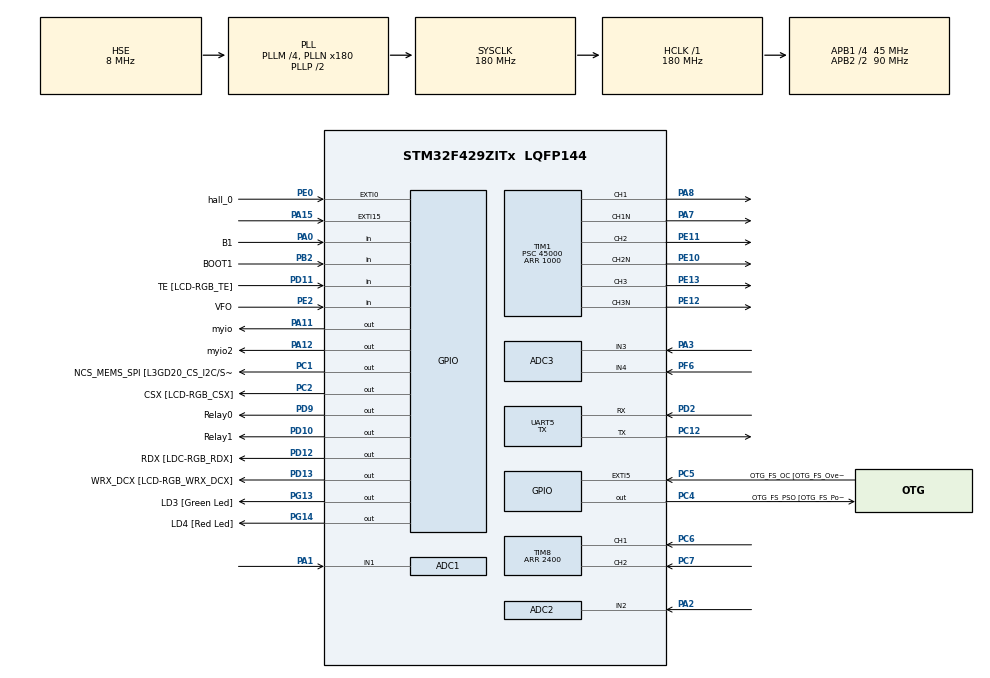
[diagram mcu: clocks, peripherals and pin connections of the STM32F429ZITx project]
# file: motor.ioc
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ADC1.Channel-12\#ChannelRegularConversion=ADC_CHANNEL_1
ADC1.Channel-13\#ChannelInjectedConversion=ADC_CHANNEL_1
ADC1.EOCSelection=ADC_EOC_SEQ_CONV
ADC1.EnableAnalogWatchDog=true
ADC1.ExternalTrigInjecConv=ADC_EXTERNALTRIGINJECCONV_T1_TRGO
ADC1.ExternalTrigInjecConvEdge=ADC_EXTERNALTRIGINJECCONVEDGE_FALLING
ADC1.InjNumberOfConversion=1
ADC1.InjectedOffset-13\#ChannelInjectedConversion=0
ADC1.InjectedRank-13\#ChannelInjectedConversion=1
ADC1.Mode=ADC_TRIPLEMODE_INJECSIMULT
ADC1.NbrOfConversionFlag=1
ADC1.Rank-12\#ChannelRegularConversion=1
ADC1.SamplingTime-12\#ChannelRegularConversion=ADC_SAMPLETIME_3CYCLES
ADC1.SamplingTime-13\#ChannelInjectedConversion=ADC_SAMPLETIME_3CYCLES
ADC1.WatchdogChannel=ADC_CHANNEL_1
ADC1.master=1
ADC2.Channel-22\#ChannelRegularConversion=ADC_CHANNEL_2
ADC2.Channel-23\#ChannelInjectedConversion=ADC_CHANNEL_2
ADC2.InjNumberOfConversion=1
ADC2.InjectedOffset-23\#ChannelInjectedConversion=0
ADC2.InjectedRank-23\#ChannelInjectedConversion=1
ADC2.Mode=ADC_TRIPLEMODE_INJECSIMULT
ADC2.NbrOfConversionFlag=1
ADC2.Rank-22\#ChannelRegularConversion=1
ADC2.SamplingTime-22\#ChannelRegularConversion=ADC_SAMPLETIME_3CYCLES
ADC2.SamplingTime-23\#ChannelInjectedConversion=ADC_SAMPLETIME_3CYCLES
ADC3.Channel-2\#ChannelRegularConversion=ADC_CHANNEL_3
ADC3.Channel-3\#ChannelInjectedConversion=ADC_CHANNEL_3
ADC3.InjNumberOfConversion=1
ADC3.InjectedOffset-3\#ChannelInjectedConversion=0
ADC3.InjectedRank-3\#ChannelInjectedConversion=1
ADC3.Mode=ADC_TRIPLEMODE_INJECSIMULT
ADC3.NbrOfConversionFlag=1
ADC3.Rank-2\#ChannelRegularConversion=1
ADC3.SamplingTime-2\#ChannelRegularConversion=ADC_SAMPLETIME_3CYCLES
ADC3.SamplingTime-3\#ChannelInjectedConversion=ADC_SAMPLETIME_3CYCLES
Mcu.Family=STM32F4
Mcu.Name=STM32F429ZITx
Mcu.Package=LQFP144
NVIC.ADC_IRQn=true\:0\:0\:false\:false\:true\:true\:true
NVIC.EXTI0_IRQn=true\:0\:0\:false\:false\:true\:true\:true
NVIC.PriorityGroup=NVIC_PRIORITYGROUP_4
NVIC.TIM1_CC_IRQn=true\:0\:0\:false\:false\:true\:true\:true
NVIC.TIM1_UP_TIM10_IRQn=true\:0\:0\:false\:false\:true\:true\:true
NVIC.TIM6_DAC_IRQn=true\:0\:0\:false\:false\:true\:false\:true
NVIC.TimeBase=TIM6_DAC_IRQn
NVIC.TimeBaseIP=TIM6
NVIC.UART5_IRQn=true\:0\:0\:false\:false\:true\:true\:true
PA0/WKUP.GPIO_Label=B1
PA0/WKUP.Signal=GPIO_Input
PA1.Signal=ADCx_IN1
PA10.GPIO_Label=STLINK_TX [STM32F103CBT6_PA2]
PA10.Signal=USART1_RX
PA11.GPIO_Label=myio
PA11.Signal=GPIO_Output
PA12.GPIO_Label=myio2
PA12.Signal=GPIO_Output
PA13.GPIO_Label=SWDIO
PA13.Mode=Serial_Wire
PA13.Signal=SYS_JTMS-SWDIO
PA14.GPIO_Label=SWCLK
PA14.Mode=Serial_Wire
PA14.Signal=SYS_JTCK-SWCLK
PA15.Signal=GPXTI15
PA2.Signal=ADCx_IN2
PA3.Signal=ADCx_IN3
PA4.GPIO_Label=VSYNC
PA4.GPIO_Mode=GPIO_MODE_AF_PP
PA4.GPIO_PuPd=GPIO_NOPULL
PA4.GPIO_Speed=GPIO_SPEED_FREQ_LOW
PA4.Signal=LTDC_VSYNC
PA6.GPIO_Label=G2
PA6.GPIO_Mode=GPIO_MODE_AF_PP
PA6.GPIO_PuPd=GPIO_NOPULL
PA6.GPIO_Speed=GPIO_SPEED_FREQ_LOW
PA6.Signal=LTDC_G2
PA7.GPIO_Speed=GPIO_SPEED_FREQ_HIGH
PA7.Mode=PWM Generation1 CH1 CH1N
PA7.Signal=TIM1_CH1N
PA8.GPIO_Speed=GPIO_SPEED_FREQ_HIGH
PA8.Signal=S_TIM1_CH1
PA9.GPIO_Label=STLINK_RX [STM32F103CBT6_PA3]
PA9.Signal=USART1_TX
PB0.GPIO_Label=R3
PB0.GPIO_Mode=GPIO_MODE_AF_PP
PB0.GPIO_PuPd=GPIO_NOPULL
PB0.GPIO_Speed=GPIO_SPEED_FREQ_LOW
PB0.Signal=LTDC_R3
PB1.Signal=TIM8_CH3N
PB10.GPIO_Label=G4
PB10.GPIO_Mode=GPIO_MODE_AF_PP
PB10.GPIO_PuPd=GPIO_NOPULL
PB10.GPIO_Speed=GPIO_SPEED_FREQ_LOW
PB10.Signal=LTDC_G4
PB11.GPIO_Label=G5
PB11.GPIO_Mode=GPIO_MODE_AF_PP
PB11.GPIO_PuPd=GPIO_NOPULL
PB11.GPIO_Speed=GPIO_SPEED_FREQ_LOW
PB11.Signal=LTDC_G5
PB12.GPIO_Label=OTG_HS_ID
PB12.GPIO_Mode=GPIO_MODE_AF_PP
PB12.GPIO_PuPd=GPIO_NOPULL
PB12.GPIO_Speed=GPIO_SPEED_FREQ_LOW
PB12.Signal=USB_OTG_HS_ID
PB13.GPIO_Label=VBUS_HS
PB13.GPIO_Mode=GPIO_MODE_INPUT
PB13.GPIO_PuPd=GPIO_NOPULL
PB13.Signal=USB_OTG_HS_VBUS
PB14.GPIO_Label=OTG_HS_DM
PB14.GPIO_Mode=GPIO_MODE_AF_PP
PB14.GPIO_PuPd=GPIO_NOPULL
PB14.GPIO_Speed=GPIO_SPEED_FREQ_LOW
PB14.Signal=USB_OTG_HS_DM
PB15.GPIO_Label=OTG_HS_DP
PB15.GPIO_Mode=GPIO_MODE_AF_PP
PB15.GPIO_PuPd=GPIO_NOPULL
PB15.GPIO_Speed=GPIO_SPEED_FREQ_LOW
PB15.Signal=USB_OTG_HS_DP
PB2/BOOT1.GPIO_Label=BOOT1
PB2/BOOT1.GPIO_Mode=GPIO_MODE_INPUT
PB2/BOOT1.GPIO_PuPd=GPIO_NOPULL
PB2/BOOT1.Signal=GPIO_Input
PB5.GPIO_Label=SDCKE1
PB5.GPIO_Mode=GPIO_MODE_AF_PP
PB5.GPIO_PuPd=GPIO_NOPULL
PB5.GPIO_Speed=GPIO_SPEED_FREQ_VERY_HIGH
PB5.Signal=FMC_SDCKE1
PB6.GPIO_Label=SDNE1 [SDRAM_CS]
PB6.GPIO_Mode=GPIO_MODE_AF_PP
PB6.GPIO_PuPd=GPIO_NOPULL
PB6.GPIO_Speed=GPIO_SPEED_FREQ_VERY_HIGH
PB6.Signal=FMC_SDNE1
PB8.GPIO_Label=B6
PB8.GPIO_Mode=GPIO_MODE_AF_PP
PB8.GPIO_PuPd=GPIO_NOPULL
PB8.GPIO_Speed=GPIO_SPEED_FREQ_LOW
PB8.Signal=LTDC_B6
PB9.GPIO_Label=B7
PB9.GPIO_Mode=GPIO_MODE_AF_PP
PB9.GPIO_PuPd=GPIO_NOPULL
PB9.GPIO_Speed=GPIO_SPEED_FREQ_LOW
PB9.Signal=LTDC_B7
PC0.GPIO_Label=SDNWE
PC0.GPIO_Mode=GPIO_MODE_AF_PP
PC0.GPIO_PuPd=GPIO_NOPULL
PC0.GPIO_Speed=GPIO_SPEED_FREQ_VERY_HIGH
PC0.Signal=FMC_SDNWE
PC1.GPIO_Label=NCS_MEMS_SPI [L3GD20_CS_I2C/SPI]
PC1.GPIO_Mode=GPIO_MODE_OUTPUT_PP
PC1.GPIO_PuPd=GPIO_NOPULL
PC1.GPIO_Speed=GPIO_SPEED_FREQ_LOW
PC1.Signal=GPIO_Output
PC10.GPIO_Label=R2
PC10.GPIO_Mode=GPIO_MODE_AF_PP
PC10.GPIO_PuPd=GPIO_NOPULL
PC10.GPIO_Speed=GPIO_SPEED_FREQ_LOW
PC10.Signal=LTDC_R2
PC12.Mode=Asynchronous
PC12.Signal=UART5_TX
PC14/OSC32_IN.GPIO_Label=PC14-OSC32_IN
PC14/OSC32_IN.Signal=RCC_OSC32_IN
PC15/OSC32_OUT.GPIO_Label=PC15-OSC32_OUT
PC15/OSC32_OUT.Signal=RCC_OSC32_OUT
PC2.GPIO_Label=CSX [LCD-RGB_CSX]
PC2.GPIO_Mode=GPIO_MODE_OUTPUT_PP
PC2.GPIO_PuPd=GPIO_NOPULL
PC2.GPIO_Speed=GPIO_SPEED_FREQ_LOW
PC2.Signal=GPIO_Output
PC4.GPIO_Label=OTG_FS_PSO [OTG_FS_PowerSwitchOn]
PC4.GPIO_Mode=GPIO_MODE_OUTPUT_PP
PC4.GPIO_PuPd=GPIO_NOPULL
PC4.GPIO_Speed=GPIO_SPEED_FREQ_LOW
PC4.Signal=GPIO_Output
PC5.GPIO_Label=OTG_FS_OC [OTG_FS_OverCurrent]
PC5.GPIO_ModeDefaultEXTI=GPIO_MODE_EVT_RISING
PC5.Signal=GPXTI5
PC6.Signal=S_TIM8_CH1
PC7.Signal=S_TIM8_CH2
PD0.GPIO_Label=D2
PD0.GPIO_Mode=GPIO_MODE_AF_PP
PD0.GPIO_PuPd=GPIO_NOPULL
PD0.GPIO_Speed=GPIO_SPEED_FREQ_VERY_HIGH
PD0.Signal=FMC_D2_DA2
PD1.GPIO_Label=D3
PD1.GPIO_Mode=GPIO_MODE_AF_PP
PD1.GPIO_PuPd=GPIO_NOPULL
PD1.GPIO_Speed=GPIO_SPEED_FREQ_VERY_HIGH
PD1.Signal=FMC_D3_DA3
PD10.GPIO_Label=Relay1
PD10.Signal=GPIO_Output
PD11.GPIO_Label=TE [LCD-RGB_TE]
PD11.GPIO_Mode=GPIO_MODE_INPUT
PD11.GPIO_PuPd=GPIO_NOPULL
PD11.Signal=GPIO_Input
PD12.GPIO_Label=RDX [LDC-RGB_RDX]
PD12.GPIO_Mode=GPIO_MODE_OUTPUT_PP
PD12.GPIO_PuPd=GPIO_NOPULL
PD12.GPIO_Speed=GPIO_SPEED_FREQ_LOW
PD12.Signal=GPIO_Output
PD13.GPIO_Label=WRX_DCX [LCD-RGB_WRX_DCX]
PD13.GPIO_Mode=GPIO_MODE_OUTPUT_PP
PD13.GPIO_PuPd=GPIO_NOPULL
PD13.GPIO_Speed=GPIO_SPEED_FREQ_LOW
PD13.Signal=GPIO_Output
PD14.GPIO_Label=D0
PD14.GPIO_Mode=GPIO_MODE_AF_PP
PD14.GPIO_PuPd=GPIO_NOPULL
PD14.GPIO_Speed=GPIO_SPEED_FREQ_VERY_HIGH
PD14.Signal=FMC_D0_DA0
PD15.GPIO_Label=D1
PD15.GPIO_Mode=GPIO_MODE_AF_PP
PD15.GPIO_PuPd=GPIO_NOPULL
PD15.GPIO_Speed=GPIO_SPEED_FREQ_VERY_HIGH
PD15.Signal=FMC_D1_DA1
PD2.Mode=Asynchronous
PD2.Signal=UART5_RX
PD3.GPIO_Label=G7
PD3.GPIO_Mode=GPIO_MODE_AF_PP
PD3.GPIO_PuPd=GPIO_NOPULL
PD3.GPIO_Speed=GPIO_SPEED_FREQ_LOW
PD3.Signal=LTDC_G7
PD6.GPIO_Label=B2
PD6.GPIO_Mode=GPIO_MODE_AF_PP
PD6.GPIO_PuPd=GPIO_NOPULL
PD6.GPIO_Speed=GPIO_SPEED_FREQ_LOW
PD6.Signal=LTDC_B2
PD8.GPIO_Label=D13
PD8.GPIO_Mode=GPIO_MODE_AF_PP
PD8.GPIO_PuPd=GPIO_NOPULL
PD8.GPIO_Speed=GPIO_SPEED_FREQ_VERY_HIGH
PD8.Signal=FMC_D13_DA13
PD9.GPIO_Label=Relay0
PD9.Signal=GPIO_Output
PE0.GPIO_Label=hall_0
PE0.GPIO_ModeDefaultEXTI=GPIO_MODE_IT_RISING
PE0.GPIO_PuPd=GPIO_PULLUP
PE0.Signal=GPXTI0
PE10.GPIO_Speed=GPIO_SPEED_FREQ_HIGH
PE10.Mode=PWM Generation2 CH2 CH2N
PE10.Signal=TIM1_CH2N
PE11.GPIO_Speed=GPIO_SPEED_FREQ_HIGH
PE11.Signal=S_TIM1_CH2
PE12.GPIO_Speed=GPIO_SPEED_FREQ_HIGH
PE12.Mode=PWM Generation3 CH3 CH3N
PE12.Signal=TIM1_CH3N
PE13.GPIO_Speed=GPIO_SPEED_FREQ_HIGH
PE13.Signal=S_TIM1_CH3
PE14.GPIO_Label=D11
PE14.GPIO_Mode=GPIO_MODE_AF_PP
PE14.GPIO_PuPd=GPIO_NOPULL
PE14.GPIO_Speed=GPIO_SPEED_FREQ_VERY_HIGH
PE14.Signal=FMC_D11_DA11
PE15.GPIO_Label=D12
PE15.GPIO_Mode=GPIO_MODE_AF_PP
PE15.GPIO_PuPd=GPIO_NOPULL
PE15.GPIO_Speed=GPIO_SPEED_FREQ_VERY_HIGH
PE15.Signal=FMC_D12_DA12
PE2.GPIO_Label=VFO
PE2.GPIO_PuPd=GPIO_PULLUP
PE2.Signal=GPIO_Input
PE7.GPIO_Label=D4
PE7.GPIO_Mode=GPIO_MODE_AF_PP
PE7.GPIO_PuPd=GPIO_NOPULL
PE7.GPIO_Speed=GPIO_SPEED_FREQ_VERY_HIGH
PE7.Signal=FMC_D4_DA4
PE8.GPIO_Label=D5
PE8.GPIO_Mode=GPIO_MODE_AF_PP
PE8.GPIO_PuPd=GPIO_NOPULL
PE8.GPIO_Speed=GPIO_SPEED_FREQ_VERY_HIGH
PE8.Signal=FMC_D5_DA5
PE9.GPIO_Label=D6
PE9.GPIO_Mode=GPIO_MODE_AF_PP
PE9.GPIO_PuPd=GPIO_NOPULL
PE9.GPIO_Speed=GPIO_SPEED_FREQ_VERY_HIGH
PE9.Signal=FMC_D6_DA6
PF0.GPIO_Label=A0
PF0.GPIO_Mode=GPIO_MODE_AF_PP
PF0.GPIO_PuPd=GPIO_NOPULL
PF0.GPIO_Speed=GPIO_SPEED_FREQ_VERY_HIGH
PF0.Signal=FMC_A0
PF1.GPIO_Label=A1
PF1.GPIO_Mode=GPIO_MODE_AF_PP
PF1.GPIO_PuPd=GPIO_NOPULL
PF1.GPIO_Speed=GPIO_SPEED_FREQ_VERY_HIGH
PF1.Signal=FMC_A1
PF10.GPIO_Label=ENABLE [LCD-RGB_ENABLE]
PF10.GPIO_Mode=GPIO_MODE_AF_PP
PF10.GPIO_PuPd=GPIO_NOPULL
PF10.GPIO_Speed=GPIO_SPEED_FREQ_LOW
PF10.Signal=LTDC_DE
PF11.GPIO_Label=SDNRAS
PF11.GPIO_Mode=GPIO_MODE_AF_PP
PF11.GPIO_PuPd=GPIO_NOPULL
PF11.GPIO_Speed=GPIO_SPEED_FREQ_VERY_HIGH
PF11.Signal=FMC_SDNRAS
PF12.GPIO_Label=A6
PF12.GPIO_Mode=GPIO_MODE_AF_PP
PF12.GPIO_PuPd=GPIO_NOPULL
PF12.GPIO_Speed=GPIO_SPEED_FREQ_VERY_HIGH
PF12.Signal=FMC_A6
PF13.GPIO_Label=A7
PF13.GPIO_Mode=GPIO_MODE_AF_PP
PF13.GPIO_PuPd=GPIO_NOPULL
PF13.GPIO_Speed=GPIO_SPEED_FREQ_VERY_HIGH
PF13.Signal=FMC_A7
PF14.GPIO_Label=A8
PF14.GPIO_Mode=GPIO_MODE_AF_PP
PF14.GPIO_PuPd=GPIO_NOPULL
PF14.GPIO_Speed=GPIO_SPEED_FREQ_VERY_HIGH
PF14.Signal=FMC_A8
PF15.GPIO_Label=A9
PF15.GPIO_Mode=GPIO_MODE_AF_PP
PF15.GPIO_PuPd=GPIO_NOPULL
PF15.GPIO_Speed=GPIO_SPEED_FREQ_VERY_HIGH
PF15.Signal=FMC_A9
PF2.GPIO_Label=A2
PF2.GPIO_Mode=GPIO_MODE_AF_PP
PF2.GPIO_PuPd=GPIO_NOPULL
PF2.GPIO_Speed=GPIO_SPEED_FREQ_VERY_HIGH
PF2.Signal=FMC_A2
PF3.GPIO_Label=A3
PF3.GPIO_Mode=GPIO_MODE_AF_PP
PF3.GPIO_PuPd=GPIO_NOPULL
PF3.GPIO_Speed=GPIO_SPEED_FREQ_VERY_HIGH
PF3.Signal=FMC_A3
PF4.GPIO_Label=A4
PF4.GPIO_Mode=GPIO_MODE_AF_PP
PF4.GPIO_PuPd=GPIO_NOPULL
PF4.GPIO_Speed=GPIO_SPEED_FREQ_VERY_HIGH
PF4.Signal=FMC_A4
PF5.GPIO_Label=A5
PF5.GPIO_Mode=GPIO_MODE_AF_PP
PF5.GPIO_PuPd=GPIO_NOPULL
PF5.GPIO_Speed=GPIO_SPEED_FREQ_VERY_HIGH
PF5.Signal=FMC_A5
PF6.Mode=IN4
PF6.Signal=ADC3_IN4
PF7.GPIO_Label=SPI5_SCK [L3GD20_SCL/SPC]
PF7.GPIO_Mode=GPIO_MODE_AF_PP
PF7.GPIO_PuPd=GPIO_NOPULL
PF7.GPIO_Speed=GPIO_SPEED_FREQ_LOW
PF7.Signal=SPI5_SCK
PF8.GPIO_Label=SPI5_MISO [L3GD20_SDO]
PF8.GPIO_Mode=GPIO_MODE_AF_PP
PF8.GPIO_PuPd=GPIO_NOPULL
PF8.GPIO_Speed=GPIO_SPEED_FREQ_LOW
PF8.Signal=SPI5_MISO
PF9.GPIO_Label=SPI5_MOSI [L3GD20_SDA/SDI/SDO]
PF9.GPIO_Mode=GPIO_MODE_AF_PP
PF9.GPIO_PuPd=GPIO_NOPULL
PF9.GPIO_Speed=GPIO_SPEED_FREQ_LOW
PF9.Signal=SPI5_MOSI
PG0.GPIO_Label=A10
PG0.GPIO_Mode=GPIO_MODE_AF_PP
PG0.GPIO_PuPd=GPIO_NOPULL
PG0.GPIO_Speed=GPIO_SPEED_FREQ_VERY_HIGH
PG0.Signal=FMC_A10
PG1.GPIO_Label=A11
PG1.GPIO_Mode=GPIO_MODE_AF_PP
PG1.GPIO_PuPd=GPIO_NOPULL
PG1.GPIO_Speed=GPIO_SPEED_FREQ_VERY_HIGH
PG1.Signal=FMC_A11
PG10.GPIO_Label=G3
PG10.GPIO_Mode=GPIO_MODE_AF_PP
PG10.GPIO_PuPd=GPIO_NOPULL
PG10.GPIO_Speed=GPIO_SPEED_FREQ_LOW
PG10.Signal=LTDC_G3
PG11.GPIO_Label=B3
PG11.GPIO_Mode=GPIO_MODE_AF_PP
PG11.GPIO_PuPd=GPIO_NOPULL
PG11.GPIO_Speed=GPIO_SPEED_FREQ_LOW
PG11.Signal=LTDC_B3
PG12.GPIO_Label=B4
PG12.GPIO_Mode=GPIO_MODE_AF_PP
PG12.GPIO_PuPd=GPIO_NOPULL
PG12.GPIO_Speed=GPIO_SPEED_FREQ_LOW
PG12.Signal=LTDC_B4
PG13.GPIO_Label=LD3 [Green Led]
PG13.GPIO_Mode=GPIO_MODE_OUTPUT_PP
PG13.GPIO_PuPd=GPIO_NOPULL
PG13.GPIO_Speed=GPIO_SPEED_FREQ_LOW
PG13.Signal=GPIO_Output
PG14.GPIO_Label=LD4 [Red Led]
PG14.GPIO_Mode=GPIO_MODE_OUTPUT_PP
PG14.GPIO_PuPd=GPIO_NOPULL
PG14.GPIO_Speed=GPIO_SPEED_FREQ_LOW
PG14.Signal=GPIO_Output
PG15.GPIO_Label=SDNCAS
PG15.GPIO_Mode=GPIO_MODE_AF_PP
PG15.GPIO_PuPd=GPIO_NOPULL
PG15.GPIO_Speed=GPIO_SPEED_FREQ_VERY_HIGH
PG15.Signal=FMC_SDNCAS
PG4.GPIO_Label=BA0
PG4.GPIO_Mode=GPIO_MODE_AF_PP
PG4.GPIO_PuPd=GPIO_NOPULL
PG4.GPIO_Speed=GPIO_SPEED_FREQ_VERY_HIGH
PG4.Signal=FMC_A14_BA0
PG5.GPIO_Label=BA1
PG5.GPIO_Mode=GPIO_MODE_AF_PP
PG5.GPIO_PuPd=GPIO_NOPULL
PG5.GPIO_Speed=GPIO_SPEED_FREQ_VERY_HIGH
PG5.Signal=FMC_A15_BA1
PG6.GPIO_Label=R7
PG6.GPIO_Mode=GPIO_MODE_AF_PP
PG6.GPIO_PuPd=GPIO_NOPULL
PG6.GPIO_Speed=GPIO_SPEED_FREQ_LOW
PG6.Signal=LTDC_R7
PG7.GPIO_Label=DOTCLK [LCT-RGB_DOTCLK]
PG7.GPIO_Mode=GPIO_MODE_AF_PP
PG7.GPIO_PuPd=GPIO_NOPULL
PG7.GPIO_Speed=GPIO_SPEED_FREQ_LOW
PG7.Signal=LTDC_CLK
PG8.GPIO_Label=SDCLK
PG8.GPIO_Mode=GPIO_MODE_AF_PP
PG8.GPIO_PuPd=GPIO_NOPULL
PG8.GPIO_Speed=GPIO_SPEED_FREQ_VERY_HIGH
PG8.Signal=FMC_SDCLK
PH0/OSC_IN.GPIO_Label=PH0-OSC_IN
PH0/OSC_IN.Mode=HSE-External-Oscillator
PH0/OSC_IN.Signal=RCC_OSC_IN
PH1/OSC_OUT.GPIO_Label=PH1-OSC_OUT
PH1/OSC_OUT.Mode=HSE-External-Oscillator
PH1/OSC_OUT.Signal=RCC_OSC_OUT
ProjectManager.HeapSize=0x200
ProjectManager.StackSize=0x400
ProjectManager.TargetToolchain=STM32CubeIDE
RCC.48MHZClocksFreq_Value=120000000
RCC.AHBFreq_Value=180000000
RCC.APB1CLKDivider=RCC_HCLK_DIV4
RCC.APB1Freq_Value=45000000
RCC.APB1TimFreq_Value=90000000
RCC.APB2CLKDivider=RCC_HCLK_DIV2
RCC.APB2Freq_Value=90000000
RCC.APB2TimFreq_Value=180000000
RCC.CortexFreq_Value=180000000
RCC.HCLKFreq_Value=180000000
RCC.HSE_VALUE=8000000
RCC.HSI_VALUE=16000000
RCC.LSE_VALUE=32768
RCC.PLLM=4
RCC.PLLN=180
RCC.PLLQ=3
RCC.PLLSAIN=50
RCC.PLLSourceVirtual=RCC_PLLSOURCE_HSE
RCC.SYSCLKFreq_VALUE=180000000
RCC.SYSCLKSource=RCC_SYSCLKSOURCE_PLLCLK
RCC.VCOOutputFreq_Value=360000000
SH.ADCx_IN1.0=ADC1_IN1,IN1
SH.ADCx_IN2.0=ADC2_IN2,IN2
SH.ADCx_IN3.0=ADC3_IN3,IN3
SH.FMC_A0.0=FMC_A0
SH.FMC_A1.0=FMC_A1
SH.FMC_A10.0=FMC_A10
SH.FMC_A11.0=FMC_A11
SH.FMC_A14_BA0.0=FMC_BA0
SH.FMC_A15_BA1.0=FMC_BA1
SH.FMC_A2.0=FMC_A2
SH.FMC_A3.0=FMC_A3
SH.FMC_A4.0=FMC_A4
SH.FMC_A5.0=FMC_A5
SH.FMC_A6.0=FMC_A6
SH.FMC_A7.0=FMC_A7
SH.FMC_A8.0=FMC_A8
SH.FMC_A9.0=FMC_A9
SH.FMC_D0_DA0.0=FMC_D0
SH.FMC_D11_DA11.0=FMC_D11
SH.FMC_D12_DA12.0=FMC_D12
SH.FMC_D13_DA13.0=FMC_D13
SH.FMC_D1_DA1.0=FMC_D1
SH.FMC_D2_DA2.0=FMC_D2
SH.FMC_D3_DA3.0=FMC_D3
SH.FMC_D4_DA4.0=FMC_D4
SH.FMC_D5_DA5.0=FMC_D5
SH.FMC_D6_DA6.0=FMC_D6
SH.FMC_SDCLK.0=FMC_SDCLK
SH.FMC_SDNCAS.0=FMC_SDNCAS
SH.FMC_SDNRAS.0=FMC_SDNRAS
SH.FMC_SDNWE.0=FMC_SDNWE
SH.S_TIM1_CH1.0=TIM1_CH1,PWM Generation1 CH1 CH1N
SH.S_TIM1_CH2.0=TIM1_CH2,PWM Generation2 CH2 CH2N
SH.S_TIM1_CH3.0=TIM1_CH3,PWM Generation3 CH3 CH3N
SH.S_TIM8_CH1.0=TIM8_CH1,Encoder_Interface
SH.S_TIM8_CH2.0=TIM8_CH2,Encoder_Interface
TIM1.AutoReloadPreload=TIM_AUTORELOAD_PRELOAD_ENABLE
TIM1.Channel-Output\ Compare4\ No\ Output=TIM_CHANNEL_4
TIM1.Channel-PWM\ Generation1\ CH1\ CH1N=TIM_CHANNEL_1
TIM1.Channel-PWM\ Generation2\ CH2\ CH2N=TIM_CHANNEL_2
TIM1.Channel-PWM\ Generation3\ CH3\ CH3N=TIM_CHANNEL_3
TIM1.CounterMode=TIM_COUNTERMODE_CENTERALIGNED2
TIM1.OCIdleState_4=TIM_OCIDLESTATE_RESET
TIM1.OCMode_4=TIM_OCMODE_TOGGLE
TIM1.OCNPolarity_1=TIM_OCNPOLARITY_HIGH
TIM1.OCNPolarity_2=TIM_OCNPOLARITY_HIGH
TIM1.OCNPolarity_3=TIM_OCNPOLARITY_HIGH
TIM1.OCPolarity_4=TIM_OCPOLARITY_LOW
TIM1.Period=1000
TIM1.Prescaler=45000
TIM1.Pulse-Output\ Compare4\ No\ Output=550
TIM1.Pulse-PWM\ Generation1\ CH1\ CH1N=500
TIM1.Pulse-PWM\ Generation2\ CH2\ CH2N=500
TIM1.Pulse-PWM\ Generation3\ CH3\ CH3N=500
TIM1.TIM_MasterOutputTrigger=TIM_TRGO_OC4REF
TIM8.EncoderMode=TIM_ENCODERMODE_TI12
TIM8.IC1Filter=5
TIM8.IC2Filter=5
TIM8.Period=2400
TIM8.TIM_MasterOutputTrigger=TIM_TRGO_RESET
TIM8.TIM_MasterSlaveMode=TIM_MASTERSLAVEMODE_DISABLE
UART5.Mode=MODE_TX
UART5.VirtualMode=Asynchronous
VP_SYS_VS_tim6.Mode=TIM6
VP_TIM1_VS_ClockSourceINT.Mode=Internal
VP_TIM1_VS_no_output4.Mode=Output Compare4 No Output
board=STM32F429I-DISC1

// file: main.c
/* USER CODE BEGIN Header */
/**
  ******************************************************************************
  * @file           : main.c
  * @brief          : Main program body
  ******************************************************************************
  * @attention
  *
  * <h2><center>&copy; Copyright (c) 2020 STMicroelectronics.
  * All rights reserved.</center></h2>
  *
  * This software component is licensed by ST under Ultimate Liberty license
  * SLA0044, the "License"; You may not use this file except in compliance with
  * the License. You may obtain a copy of the License at:
  *                             www.st.com/SLA0044
  *
  ******************************************************************************
  */
/* USER CODE END Header */

#include "main.h"

ADC_HandleTypeDef hadc1;
ADC_HandleTypeDef hadc2;
ADC_HandleTypeDef hadc3;

TIM_HandleTypeDef htim1;
TIM_HandleTypeDef htim8;

UART_HandleTypeDef huart5;

void SystemClock_Config(void);
static void MX_GPIO_Init(void);
static void MX_TIM1_Init(void);
static void MX_TIM8_Init(void);
static void MX_UART5_Init(void);
static void MX_ADC1_Init(void);
static void MX_ADC2_Init(void);
static void MX_ADC3_Init(void);

/* USER CODE BEGIN 0 */

int last_state = 0;
uint16_t T = 1000;
volatile uint32_t counter = 0;

volatile uint16_t prescaler = 6;
volatile uint8_t sector = 1;
volatile uint8_t zeroed = 0;
volatile uint16_t angle = 0;
volatile uint16_t angle_rotor = 0;
volatile float incr = 0.10;
volatile float angle_temp = 0;
volatile float m =0.3;  // commanded vector magnitude
float dir = 1;
int overflow = 0;
float ki = 0.5;
float kp = 40;
float kd = 0;
float integral = 0;
float prev_error = 0;
int error = 0;
uint32_t last_angle = 0;
int vel = 0;
uint32_t elapsed_ms = 0;
int underflow = 0;
int fault = 0;

float set_v = 21;
uint32_t adc[3];

volatile uint_fast16_t u = 0;
volatile uint_fast16_t v = 0;
volatile uint_fast16_t w = 0;

volatile uint_fast16_t t0 = 0;
volatile uint_fast16_t t1 = 0;
volatile uint_fast16_t t2 = 0;
float sin_table[359];
#define MAX_TX 1000
uint16_t cycle_count = 0;
uint32_t tx_bytes = 0;
int started = 0;
uint8_t tx_buffer[MAX_TX];

void fill_sin_table()
{
    for(int i=0; i<360; i++)
        sin_table[i] = sin(0.0174532925*i);
}

void pid(){
	error = set_v - vel;
	float prop = error*kp;

	integral += error*ki;
	if (integral > 500){
		integral = 500;
	}
	if (integral < -500){
		integral = -500;
	}

	float derivative = (error - prev_error)*kd;
	float res = prop + integral + derivative;

	prev_error = error;
//	if (error == 0) // completely kill
//	{
//		return 0;
//	}
	res = (res+500)/1000.0;
	if (res < 0){
		res = 0; // left
	}
	else if (res > 1)
	{
		res = 0.4; // right
	}
	m = res;
}

void cal_pwms()
{

	if (angle < 0)
	{
		angle = 360 + angle;
	}

	if (angle > 360)
	{
		angle = angle - 360;
	}

	if (angle <= 60)
	{
		sector = 1;
		angle_temp = angle;
	}
	else if (angle <= 120)
	{
		sector = 2;
		angle_temp = angle-60;
	}
	else if (angle <= 180)
	{
		sector = 3;
		angle_temp = angle-120;
	}
	else if (angle <= 240)
	{
		sector = 4;
		angle_temp = angle-180;
	}
	else if (angle <= 300)
	{
		sector = 5;
		angle_temp = angle-240;
	}
	else
	{
		sector = 6;
		angle_temp = angle-300;
	}

	t1 = T*m*sin_table[(int)(60-angle_temp)];
	t2 = T*m*sin_table[(int)angle_temp];

	t0 = T-t1-t2;

	switch (sector)
	{
		case 1:
	    	u = t1 + t2 +0.5*t0;
	    	v = t2 + 0.5*t0;
	    	w = 0.5*t0;
	      break;
	    case 2:
	    	u = t1 + 0.5*t0;
	    	v = t1 + t2 + 0.5*t0;
	    	w = 0.5*t0;
	      break;
	    case 3:
	    	u = 0.5*t0;
	    	v = t1 + t2 + 0.5*t0;
	    	w = t2 + 0.5*t0;
	      break;
	    case 4:
	    	u = 0.5*t0;
	    	v = t1 + 0.5*t0;
	    	w = t1 + t2 + 0.5*t0;
	      break;
	    case 5:
	    	u = t2 + 0.5*t0;
	    	v = 0.5*t0;
	    	w = t1 + t2 + 0.5*t0;
	      break;
	    case 6:
	    	u = t1 + t2 + 0.5*t0;
	    	v = 0.5*t0;
	    	w = t1 + 0.5*t0;
	      break;
	    default:
	    	u = 0;
	    	v = 0;
	    	w = 0;
	}
	if (fault == 1)
	{
    	u = 0;
    	v = 0;
    	w = 0;
	}

	__HAL_TIM_SET_COMPARE(&htim1, TIM_CHANNEL_1, u);
	__HAL_TIM_SET_COMPARE(&htim1, TIM_CHANNEL_2, v);
	__HAL_TIM_SET_COMPARE(&htim1, TIM_CHANNEL_3, w);
}

void start(int dir)
{
	HAL_GPIO_WritePin(Relay1_GPIO_Port, Relay1_Pin, 0);
	HAL_GPIO_WritePin(Relay0_GPIO_Port, Relay0_Pin, 1);
	HAL_Delay(1000);
	HAL_GPIO_WritePin(Relay1_GPIO_Port, Relay1_Pin, 1);

	if (HAL_GPIO_ReadPin(hall_0_GPIO_Port, hall_0_Pin))
	{
		__HAL_TIM_SET_COUNTER(&htim8, 600);
	}
	else
	{
		__HAL_TIM_SET_COUNTER(&htim8, 1800);
	}
	HAL_Delay(100);

	started = 1;
	return;
	m = 0.01;
	for (int x = 0; x<360; x++)
	{
		angle = x;
		cal_pwms();
		m+=0.01;
		HAL_Delay(1);
	}
	for (int x = 0; x<360; x++)
	{
		angle = x;
		cal_pwms();
		m+=0.1;
		HAL_Delay(1);
	}
	m = 0;
	started = 1;
}

void myisr()
{
	if (started)
	{
		angle_rotor =(uint16_t)__HAL_TIM_GET_COUNTER(&htim8)/6.66666666666666;
		angle = angle_rotor + 90;
		cal_pwms();
	}
}

/* USER CODE END 0 */

int main(void)
{
  /* USER CODE BEGIN 1 */
	fill_sin_table();
  /* USER CODE END 1 */

  /* MCU Configuration--------------------------------------------------------*/

  /* Reset of all peripherals, Initializes the Flash interface and the Systick. */
  HAL_Init();

  /* Configure the system clock */
  SystemClock_Config();

  /* Initialize all configured peripherals */
  MX_GPIO_Init();
  MX_TIM1_Init();
  MX_TIM8_Init();
  MX_UART5_Init();
  MX_ADC1_Init();
  MX_ADC2_Init();
  MX_ADC3_Init();
  /* USER CODE BEGIN 2 */
  // arr = freq
  // ccr = duty

  HAL_TIM_Base_Start_IT(&htim1);

  HAL_TIM_PWM_Start(&htim1, TIM_CHANNEL_1);
  HAL_TIMEx_PWMN_Start(&htim1, TIM_CHANNEL_1);

  HAL_TIM_PWM_Start(&htim1, TIM_CHANNEL_2);
  HAL_TIMEx_PWMN_Start(&htim1, TIM_CHANNEL_2);

  HAL_TIM_PWM_Start(&htim1, TIM_CHANNEL_3);
  HAL_TIMEx_PWMN_Start(&htim1, TIM_CHANNEL_3);

  HAL_TIM_OC_Start_IT(&htim1, TIM_CHANNEL_4);

  __HAL_TIM_SET_COMPARE(&htim1, TIM_CHANNEL_1, 100);
  __HAL_TIM_SET_COMPARE(&htim1, TIM_CHANNEL_2, 500);
  __HAL_TIM_SET_COMPARE(&htim1, TIM_CHANNEL_3, 800);

//  HAL_TIM_Base_Start(&htim8);  // encoder timer
  HAL_TIM_Encoder_Start(&htim8,TIM_CHANNEL_ALL);

  HAL_ADCEx_InjectedStart_IT(&hadc1);

//  HAL_ADC_Start_DMA(&hadc2, (uint32_t *)adc, 2);
//  HAL_ADC_Start_IT(&hadc2);

  HAL_ADCEx_InjectedStart_IT(&hadc2);
  HAL_ADCEx_InjectedStart_IT(&hadc3);

//  HAL_AD
//  HAL_UART_Transmit_DMA(&huart5, tx_buffer, 100);
//  HAL_UART_Transmit(&huart5, tx_buffer, 100);

//  HAL_ADC_IRQHandler(hadc)
  /* USER CODE END 2 */

  /* Infinite loop */
  /* USER CODE BEGIN WHILE */

  __HAL_TIM_SET_PRESCALER(&htim1, prescaler);

  start(1);
  while (1)
  {

	  counter+=1;
	  if (counter < 45000)
	  {
		  HAL_GPIO_WritePin(LD3_GPIO_Port, LD3_Pin, 1);
		  if (counter == 42000)
		  {
			  char str[80];

		  }
	  }
	  else
	  {
		  HAL_GPIO_WritePin(LD3_GPIO_Port, LD3_Pin, 0);
	  }
	  if (counter > 90000)
	  {
		  counter = 0;
	  }

	  int val = HAL_GPIO_ReadPin(B1_GPIO_Port, B1_Pin);
	  if (val != last_state)
	  {
		  if (fault == 1)  // fault happened
		  {
			  if (HAL_GPIO_ReadPin(VFO_GPIO_Port, VFO_Pin))  // no fault now
				{
				  fault = 0;
	      		  HAL_GPIO_WritePin(LD4_GPIO_Port, LD4_Pin, 0);
				}
		  }
		  if (val)
		  {
//			  HAL_GPIO_WritePin(LD3_GPIO_Port, LD3_Pin, val);
//			  HAL_GPIO_TogglePin(LD3_GPIO_Port, LD3_Pin);

//			  incr+=0.001;
//			  if (incr > 1.0)
//			  {
//			  m = 1.0;
//			  }
//				__HAL_TIM_SET_COUNTER(&htim8, 0);
//			  m+=0.1;
//			  if (m>1.0)
//			  {
//				  m=0;
//			  }
			  set_v+=1;
			  if (set_v>50.0)
			  {
				  set_v=2;
			  }

//			  angle+=10;
		  }
		  last_state = val;
	  }

    /* USER CODE END WHILE */

  }
}

void SystemClock_Config(void)
{
  RCC_OscInitTypeDef RCC_OscInitStruct = {0};
  RCC_ClkInitTypeDef RCC_ClkInitStruct = {0};

  /** Configure the main internal regulator output voltage
  */
  __HAL_RCC_PWR_CLK_ENABLE();
  __HAL_PWR_VOLTAGESCALING_CONFIG(PWR_REGULATOR_VOLTAGE_SCALE1);
  /** Initializes the CPU, AHB and APB busses clocks
  */
  RCC_OscInitStruct.OscillatorType = RCC_OSCILLATORTYPE_HSE;
  RCC_OscInitStruct.HSEState = RCC_HSE_ON;
  RCC_OscInitStruct.PLL.PLLState = RCC_PLL_ON;
  RCC_OscInitStruct.PLL.PLLSource = RCC_PLLSOURCE_HSE;
  RCC_OscInitStruct.PLL.PLLM = 4;
  RCC_OscInitStruct.PLL.PLLN = 180;
  RCC_OscInitStruct.PLL.PLLP = RCC_PLLP_DIV2;
  RCC_OscInitStruct.PLL.PLLQ = 3;
  if (HAL_RCC_OscConfig(&RCC_OscInitStruct) != HAL_OK)
  {
    Error_Handler();
  }
  /** Activate the Over-Drive mode
  */
  if (HAL_PWREx_EnableOverDrive() != HAL_OK)
  {
    Error_Handler();
  }
  /** Initializes the CPU, AHB and APB busses clocks
  */
  RCC_ClkInitStruct.ClockType = RCC_CLOCKTYPE_HCLK|RCC_CLOCKTYPE_SYSCLK
                              |RCC_CLOCKTYPE_PCLK1|RCC_CLOCKTYPE_PCLK2;
  RCC_ClkInitStruct.SYSCLKSource = RCC_SYSCLKSOURCE_PLLCLK;
  RCC_ClkInitStruct.AHBCLKDivider = RCC_SYSCLK_DIV1;
  RCC_ClkInitStruct.APB1CLKDivider = RCC_HCLK_DIV4;
  RCC_ClkInitStruct.APB2CLKDivider = RCC_HCLK_DIV2;

  if (HAL_RCC_ClockConfig(&RCC_ClkInitStruct, FLASH_LATENCY_5) != HAL_OK)
  {
    Error_Handler();
  }
}

static void MX_ADC1_Init(void)
{

  ADC_MultiModeTypeDef multimode = {0};
  ADC_AnalogWDGConfTypeDef AnalogWDGConfig = {0};
  ADC_ChannelConfTypeDef sConfig = {0};
  ADC_InjectionConfTypeDef sConfigInjected = {0};

  /** Configure the global features of the ADC (Clock, Resolution, Data Alignment and number of conversion)
  */
  hadc1.Instance = ADC1;
  hadc1.Init.ClockPrescaler = ADC_CLOCK_SYNC_PCLK_DIV4;
  hadc1.Init.Resolution = ADC_RESOLUTION_12B;
  hadc1.Init.ScanConvMode = DISABLE;
  hadc1.Init.ContinuousConvMode = DISABLE;
  hadc1.Init.DiscontinuousConvMode = DISABLE;
  hadc1.Init.ExternalTrigConvEdge = ADC_EXTERNALTRIGCONVEDGE_NONE;
  hadc1.Init.ExternalTrigConv = ADC_SOFTWARE_START;
  hadc1.Init.DataAlign = ADC_DATAALIGN_RIGHT;
  hadc1.Init.NbrOfConversion = 1;
  hadc1.Init.DMAContinuousRequests = DISABLE;
  hadc1.Init.EOCSelection = ADC_EOC_SEQ_CONV;
  if (HAL_ADC_Init(&hadc1) != HAL_OK)
  {
    Error_Handler();
  }
  /** Configure the ADC multi-mode
  */
  multimode.Mode = ADC_TRIPLEMODE_INJECSIMULT;
  multimode.TwoSamplingDelay = ADC_TWOSAMPLINGDELAY_5CYCLES;
  if (HAL_ADCEx_MultiModeConfigChannel(&hadc1, &multimode) != HAL_OK)
  {
    Error_Handler();
  }
  /** Configure the analog watchdog
  */
  AnalogWDGConfig.WatchdogMode = ADC_ANALOGWATCHDOG_SINGLE_REG;
  AnalogWDGConfig.HighThreshold = 0;
  AnalogWDGConfig.LowThreshold = 0;
  AnalogWDGConfig.Channel = ADC_CHANNEL_1;
  AnalogWDGConfig.ITMode = DISABLE;
  if (HAL_ADC_AnalogWDGConfig(&hadc1, &AnalogWDGConfig) != HAL_OK)
  {
    Error_Handler();
  }
  /** Configure for the selected ADC regular channel its corresponding rank in the sequencer and its sample time.
  */
  sConfig.Channel = ADC_CHANNEL_1;
  sConfig.Rank = 1;
  sConfig.SamplingTime = ADC_SAMPLETIME_3CYCLES;
  if (HAL_ADC_ConfigChannel(&hadc1, &sConfig) != HAL_OK)
  {
    Error_Handler();
  }
  /** Configures for the selected ADC injected channel its corresponding rank in the sequencer and its sample time
  */
  sConfigInjected.InjectedChannel = ADC_CHANNEL_1;
  sConfigInjected.InjectedRank = 1;
  sConfigInjected.InjectedNbrOfConversion = 1;
  sConfigInjected.InjectedSamplingTime = ADC_SAMPLETIME_3CYCLES;
  sConfigInjected.ExternalTrigInjecConvEdge = ADC_EXTERNALTRIGINJECCONVEDGE_FALLING;
  sConfigInjected.ExternalTrigInjecConv = ADC_EXTERNALTRIGINJECCONV_T1_TRGO;
  sConfigInjected.AutoInjectedConv = DISABLE;
  sConfigInjected.InjectedDiscontinuousConvMode = DISABLE;
  sConfigInjected.InjectedOffset = 0;
  if (HAL_ADCEx_InjectedConfigChannel(&hadc1, &sConfigInjected) != HAL_OK)
  {
    Error_Handler();
  }

}

static void MX_ADC2_Init(void)
{

  ADC_ChannelConfTypeDef sConfig = {0};
  ADC_InjectionConfTypeDef sConfigInjected = {0};

  /** Configure the global features of the ADC (Clock, Resolution, Data Alignment and number of conversion)
  */
  hadc2.Instance = ADC2;
  hadc2.Init.ClockPrescaler = ADC_CLOCK_SYNC_PCLK_DIV4;
  hadc2.Init.Resolution = ADC_RESOLUTION_12B;
  hadc2.Init.ScanConvMode = DISABLE;
  hadc2.Init.ContinuousConvMode = DISABLE;
  hadc2.Init.DiscontinuousConvMode = DISABLE;
  hadc2.Init.DataAlign = ADC_DATAALIGN_RIGHT;
  hadc2.Init.NbrOfConversion = 1;
  hadc2.Init.DMAContinuousRequests = DISABLE;
  hadc2.Init.EOCSelection = ADC_EOC_SINGLE_CONV;
  if (HAL_ADC_Init(&hadc2) != HAL_OK)
  {
    Error_Handler();
  }
  /** Configure for the selected ADC regular channel its corresponding rank in the sequencer and its sample time.
  */
  sConfig.Channel = ADC_CHANNEL_2;
  sConfig.Rank = 1;
  sConfig.SamplingTime = ADC_SAMPLETIME_3CYCLES;
  if (HAL_ADC_ConfigChannel(&hadc2, &sConfig) != HAL_OK)
  {
    Error_Handler();
  }
  /** Configures for the selected ADC injected channel its corresponding rank in the sequencer and its sample time
  */
  sConfigInjected.InjectedChannel = ADC_CHANNEL_2;
  sConfigInjected.InjectedRank = 1;
  sConfigInjected.InjectedNbrOfConversion = 1;
  sConfigInjected.InjectedSamplingTime = ADC_SAMPLETIME_3CYCLES;
  sConfigInjected.AutoInjectedConv = DISABLE;
  sConfigInjected.InjectedDiscontinuousConvMode = DISABLE;
  sConfigInjected.InjectedOffset = 0;
  if (HAL_ADCEx_InjectedConfigChannel(&hadc2, &sConfigInjected) != HAL_OK)
  {
    Error_Handler();
  }

}

static void MX_ADC3_Init(void)
{

  ADC_ChannelConfTypeDef sConfig = {0};
  ADC_InjectionConfTypeDef sConfigInjected = {0};

  /** Configure the global features of the ADC (Clock, Resolution, Data Alignment and number of conversion)
  */
  hadc3.Instance = ADC3;
  hadc3.Init.ClockPrescaler = ADC_CLOCK_SYNC_PCLK_DIV4;
  hadc3.Init.Resolution = ADC_RESOLUTION_12B;
  hadc3.Init.ScanConvMode = DISABLE;
  hadc3.Init.ContinuousConvMode = DISABLE;
  hadc3.Init.DiscontinuousConvMode = DISABLE;
  hadc3.Init.DataAlign = ADC_DATAALIGN_RIGHT;
  hadc3.Init.NbrOfConversion = 1;
  hadc3.Init.DMAContinuousRequests = DISABLE;
  hadc3.Init.EOCSelection = ADC_EOC_SINGLE_CONV;
  if (HAL_ADC_Init(&hadc3) != HAL_OK)
  {
    Error_Handler();
  }
  /** Configure for the selected ADC regular channel its corresponding rank in the sequencer and its sample time.
  */
  sConfig.Channel = ADC_CHANNEL_3;
  sConfig.Rank = 1;
  sConfig.SamplingTime = ADC_SAMPLETIME_3CYCLES;
  if (HAL_ADC_ConfigChannel(&hadc3, &sConfig) != HAL_OK)
  {
    Error_Handler();
  }
  /** Configures for the selected ADC injected channel its corresponding rank in the sequencer and its sample time
  */
  sConfigInjected.InjectedChannel = ADC_CHANNEL_3;
  sConfigInjected.InjectedRank = 1;
  sConfigInjected.InjectedNbrOfConversion = 1;
  sConfigInjected.InjectedSamplingTime = ADC_SAMPLETIME_3CYCLES;
  sConfigInjected.AutoInjectedConv = DISABLE;
  sConfigInjected.InjectedDiscontinuousConvMode = DISABLE;
  sConfigInjected.InjectedOffset = 0;
  if (HAL_ADCEx_InjectedConfigChannel(&hadc3, &sConfigInjected) != HAL_OK)
  {
    Error_Handler();
  }

}

static void MX_TIM1_Init(void)
{

  TIM_ClockConfigTypeDef sClockSourceConfig = {0};
  TIM_MasterConfigTypeDef sMasterConfig = {0};
  TIM_OC_InitTypeDef sConfigOC = {0};
  TIM_BreakDeadTimeConfigTypeDef sBreakDeadTimeConfig = {0};

  htim1.Instance = TIM1;
  htim1.Init.Prescaler = 45000;
  htim1.Init.CounterMode = TIM_COUNTERMODE_CENTERALIGNED2;
  htim1.Init.Period = 1000;
  htim1.Init.ClockDivision = TIM_CLOCKDIVISION_DIV1;
  htim1.Init.RepetitionCounter = 0;
  htim1.Init.AutoReloadPreload = TIM_AUTORELOAD_PRELOAD_ENABLE;
  if (HAL_TIM_Base_Init(&htim1) != HAL_OK)
  {
    Error_Handler();
  }
  sClockSourceConfig.ClockSource = TIM_CLOCKSOURCE_INTERNAL;
  if (HAL_TIM_ConfigClockSource(&htim1, &sClockSourceConfig) != HAL_OK)
  {
    Error_Handler();
  }
  if (HAL_TIM_PWM_Init(&htim1) != HAL_OK)
  {
    Error_Handler();
  }
  if (HAL_TIM_OC_Init(&htim1) != HAL_OK)
  {
    Error_Handler();
  }
  sMasterConfig.MasterOutputTrigger = TIM_TRGO_OC4REF;
  sMasterConfig.MasterSlaveMode = TIM_MASTERSLAVEMODE_DISABLE;
  if (HAL_TIMEx_MasterConfigSynchronization(&htim1, &sMasterConfig) != HAL_OK)
  {
    Error_Handler();
  }
  sConfigOC.OCMode = TIM_OCMODE_PWM1;
  sConfigOC.Pulse = 500;
  sConfigOC.OCPolarity = TIM_OCPOLARITY_HIGH;
  sConfigOC.OCNPolarity = TIM_OCNPOLARITY_HIGH;
  sConfigOC.OCFastMode = TIM_OCFAST_DISABLE;
  sConfigOC.OCIdleState = TIM_OCIDLESTATE_RESET;
  sConfigOC.OCNIdleState = TIM_OCNIDLESTATE_RESET;
  if (HAL_TIM_PWM_ConfigChannel(&htim1, &sConfigOC, TIM_CHANNEL_1) != HAL_OK)
  {
    Error_Handler();
  }
  if (HAL_TIM_PWM_ConfigChannel(&htim1, &sConfigOC, TIM_CHANNEL_2) != HAL_OK)
  {
    Error_Handler();
  }
  if (HAL_TIM_PWM_ConfigChannel(&htim1, &sConfigOC, TIM_CHANNEL_3) != HAL_OK)
  {
    Error_Handler();
  }
  sConfigOC.OCMode = TIM_OCMODE_TOGGLE;
  sConfigOC.Pulse = 550;
  sConfigOC.OCPolarity = TIM_OCPOLARITY_LOW;
  if (HAL_TIM_OC_ConfigChannel(&htim1, &sConfigOC, TIM_CHANNEL_4) != HAL_OK)
  {
    Error_Handler();
  }
  sBreakDeadTimeConfig.OffStateRunMode = TIM_OSSR_DISABLE;
  sBreakDeadTimeConfig.OffStateIDLEMode = TIM_OSSI_DISABLE;
  sBreakDeadTimeConfig.LockLevel = TIM_LOCKLEVEL_OFF;
  sBreakDeadTimeConfig.DeadTime = 0;
  sBreakDeadTimeConfig.BreakState = TIM_BREAK_DISABLE;
  sBreakDeadTimeConfig.BreakPolarity = TIM_BREAKPOLARITY_HIGH;
  sBreakDeadTimeConfig.AutomaticOutput = TIM_AUTOMATICOUTPUT_DISABLE;
  if (HAL_TIMEx_ConfigBreakDeadTime(&htim1, &sBreakDeadTimeConfig) != HAL_OK)
  {
    Error_Handler();
  }
  HAL_TIM_MspPostInit(&htim1);

}

static void MX_TIM8_Init(void)
{

  TIM_Encoder_InitTypeDef sConfig = {0};
  TIM_MasterConfigTypeDef sMasterConfig = {0};

  htim8.Instance = TIM8;
  htim8.Init.Prescaler = 0;
  htim8.Init.CounterMode = TIM_COUNTERMODE_UP;
  htim8.Init.Period = 2400;
  htim8.Init.ClockDivision = TIM_CLOCKDIVISION_DIV1;
  htim8.Init.RepetitionCounter = 0;
  htim8.Init.AutoReloadPreload = TIM_AUTORELOAD_PRELOAD_DISABLE;
  sConfig.EncoderMode = TIM_ENCODERMODE_TI12;
  sConfig.IC1Polarity = TIM_ICPOLARITY_RISING;
  sConfig.IC1Selection = TIM_ICSELECTION_DIRECTTI;
  sConfig.IC1Prescaler = TIM_ICPSC_DIV1;
  sConfig.IC1Filter = 5;
  sConfig.IC2Polarity = TIM_ICPOLARITY_RISING;
  sConfig.IC2Selection = TIM_ICSELECTION_DIRECTTI;
  sConfig.IC2Prescaler = TIM_ICPSC_DIV1;
  sConfig.IC2Filter = 5;
  if (HAL_TIM_Encoder_Init(&htim8, &sConfig) != HAL_OK)
  {
    Error_Handler();
  }
  sMasterConfig.MasterOutputTrigger = TIM_TRGO_RESET;
  sMasterConfig.MasterSlaveMode = TIM_MASTERSLAVEMODE_DISABLE;
  if (HAL_TIMEx_MasterConfigSynchronization(&htim8, &sMasterConfig) != HAL_OK)
  {
    Error_Handler();
  }

}

static void MX_UART5_Init(void)
{

  huart5.Instance = UART5;
  huart5.Init.BaudRate = 115200;
  huart5.Init.WordLength = UART_WORDLENGTH_8B;
  huart5.Init.StopBits = UART_STOPBITS_1;
  huart5.Init.Parity = UART_PARITY_NONE;
  huart5.Init.Mode = UART_MODE_TX;
  huart5.Init.HwFlowCtl = UART_HWCONTROL_NONE;
  huart5.Init.OverSampling = UART_OVERSAMPLING_16;
  if (HAL_UART_Init(&huart5) != HAL_OK)
  {
    Error_Handler();
  }

}

static void MX_GPIO_Init(void)
{
  GPIO_InitTypeDef GPIO_InitStruct = {0};

  /* GPIO Ports Clock Enable */
  __HAL_RCC_GPIOE_CLK_ENABLE();
  __HAL_RCC_GPIOC_CLK_ENABLE();
  __HAL_RCC_GPIOF_CLK_ENABLE();
  __HAL_RCC_GPIOH_CLK_ENABLE();
  __HAL_RCC_GPIOA_CLK_ENABLE();
  __HAL_RCC_GPIOB_CLK_ENABLE();
  __HAL_RCC_GPIOG_CLK_ENABLE();
  __HAL_RCC_GPIOD_CLK_ENABLE();

  /*Configure GPIO pin Output Level */
  HAL_GPIO_WritePin(GPIOC, NCS_MEMS_SPI_Pin|CSX_Pin|OTG_FS_PSO_Pin, GPIO_PIN_RESET);

  /*Configure GPIO pin Output Level */
  HAL_GPIO_WritePin(GPIOD, Relay0_Pin|Relay1_Pin|RDX_Pin|WRX_DCX_Pin, GPIO_PIN_RESET);

  /*Configure GPIO pin Output Level */
  HAL_GPIO_WritePin(GPIOA, myio_Pin|myio2_Pin, GPIO_PIN_RESET);

  /*Configure GPIO pin Output Level */
  HAL_GPIO_WritePin(GPIOG, LD3_Pin|LD4_Pin, GPIO_PIN_RESET);

  /*Configure GPIO pin : VFO_Pin */
  GPIO_InitStruct.Pin = VFO_Pin;
  GPIO_InitStruct.Mode = GPIO_MODE_INPUT;
  GPIO_InitStruct.Pull = GPIO_PULLUP;
  HAL_GPIO_Init(VFO_GPIO_Port, &GPIO_InitStruct);

  /*Configure GPIO pins : A0_Pin A1_Pin A2_Pin A3_Pin
                           A4_Pin A5_Pin SDNRAS_Pin A6_Pin
                           A7_Pin A8_Pin A9_Pin */
  GPIO_InitStruct.Pin = A0_Pin|A1_Pin|A2_Pin|A3_Pin
                          |A4_Pin|A5_Pin|SDNRAS_Pin|A6_Pin
                          |A7_Pin|A8_Pin|A9_Pin;
  GPIO_InitStruct.Mode = GPIO_MODE_AF_PP;
  GPIO_InitStruct.Pull = GPIO_NOPULL;
  GPIO_InitStruct.Speed = GPIO_SPEED_FREQ_VERY_HIGH;
  GPIO_InitStruct.Alternate = GPIO_AF12_FMC;
  HAL_GPIO_Init(GPIOF, &GPIO_InitStruct);

  /*Configure GPIO pins : SPI5_SCK_Pin SPI5_MISO_Pin SPI5_MOSI_Pin */
  GPIO_InitStruct.Pin = SPI5_SCK_Pin|SPI5_MISO_Pin|SPI5_MOSI_Pin;
  GPIO_InitStruct.Mode = GPIO_MODE_AF_PP;
  GPIO_InitStruct.Pull = GPIO_NOPULL;
  GPIO_InitStruct.Speed = GPIO_SPEED_FREQ_LOW;
  GPIO_InitStruct.Alternate = GPIO_AF5_SPI5;
  HAL_GPIO_Init(GPIOF, &GPIO_InitStruct);

  /*Configure GPIO pin : ENABLE_Pin */
  GPIO_InitStruct.Pin = ENABLE_Pin;
  GPIO_InitStruct.Mode = GPIO_MODE_AF_PP;
  GPIO_InitStruct.Pull = GPIO_NOPULL;
  GPIO_InitStruct.Speed = GPIO_SPEED_FREQ_LOW;
  GPIO_InitStruct.Alternate = GPIO_AF14_LTDC;
  HAL_GPIO_Init(ENABLE_GPIO_Port, &GPIO_InitStruct);

  /*Configure GPIO pin : SDNWE_Pin */
  GPIO_InitStruct.Pin = SDNWE_Pin;
  GPIO_InitStruct.Mode = GPIO_MODE_AF_PP;
  GPIO_InitStruct.Pull = GPIO_NOPULL;
  GPIO_InitStruct.Speed = GPIO_SPEED_FREQ_VERY_HIGH;
  GPIO_InitStruct.Alternate = GPIO_AF12_FMC;
  HAL_GPIO_Init(SDNWE_GPIO_Port, &GPIO_InitStruct);

  /*Configure GPIO pins : NCS_MEMS_SPI_Pin CSX_Pin OTG_FS_PSO_Pin */
  GPIO_InitStruct.Pin = NCS_MEMS_SPI_Pin|CSX_Pin|OTG_FS_PSO_Pin;
  GPIO_InitStruct.Mode = GPIO_MODE_OUTPUT_PP;
  GPIO_InitStruct.Pull = GPIO_NOPULL;
  GPIO_InitStruct.Speed = GPIO_SPEED_FREQ_LOW;
  HAL_GPIO_Init(GPIOC, &GPIO_InitStruct);

  /*Configure GPIO pin : B1_Pin */
  GPIO_InitStruct.Pin = B1_Pin;
  GPIO_InitStruct.Mode = GPIO_MODE_INPUT;
  GPIO_InitStruct.Pull = GPIO_NOPULL;
  HAL_GPIO_Init(B1_GPIO_Port, &GPIO_InitStruct);

  /*Configure GPIO pins : VSYNC_Pin G2_Pin */
  GPIO_InitStruct.Pin = VSYNC_Pin|G2_Pin;
  GPIO_InitStruct.Mode = GPIO_MODE_AF_PP;
  GPIO_InitStruct.Pull = GPIO_NOPULL;
  GPIO_InitStruct.Speed = GPIO_SPEED_FREQ_LOW;
  GPIO_InitStruct.Alternate = GPIO_AF14_LTDC;
  HAL_GPIO_Init(GPIOA, &GPIO_InitStruct);

  /*Configure GPIO pin : OTG_FS_OC_Pin */
  GPIO_InitStruct.Pin = OTG_FS_OC_Pin;
  GPIO_InitStruct.Mode = GPIO_MODE_EVT_RISING;
  GPIO_InitStruct.Pull = GPIO_NOPULL;
  HAL_GPIO_Init(OTG_FS_OC_GPIO_Port, &GPIO_InitStruct);

  /*Configure GPIO pin : R3_Pin */
  GPIO_InitStruct.Pin = R3_Pin;
  GPIO_InitStruct.Mode = GPIO_MODE_AF_PP;
  GPIO_InitStruct.Pull = GPIO_NOPULL;
  GPIO_InitStruct.Speed = GPIO_SPEED_FREQ_LOW;
  GPIO_InitStruct.Alternate = GPIO_AF9_LTDC;
  HAL_GPIO_Init(R3_GPIO_Port, &GPIO_InitStruct);

  /*Configure GPIO pin : BOOT1_Pin */
  GPIO_InitStruct.Pin = BOOT1_Pin;
  GPIO_InitStruct.Mode = GPIO_MODE_INPUT;
  GPIO_InitStruct.Pull = GPIO_NOPULL;
  HAL_GPIO_Init(BOOT1_GPIO_Port, &GPIO_InitStruct);

  /*Configure GPIO pins : A10_Pin A11_Pin BA0_Pin BA1_Pin
                           SDCLK_Pin SDNCAS_Pin */
  GPIO_InitStruct.Pin = A10_Pin|A11_Pin|BA0_Pin|BA1_Pin
                          |SDCLK_Pin|SDNCAS_Pin;
  GPIO_InitStruct.Mode = GPIO_MODE_AF_PP;
  GPIO_InitStruct.Pull = GPIO_NOPULL;
  GPIO_InitStruct.Speed = GPIO_SPEED_FREQ_VERY_HIGH;
  GPIO_InitStruct.Alternate = GPIO_AF12_FMC;
  HAL_GPIO_Init(GPIOG, &GPIO_InitStruct);

  /*Configure GPIO pins : D4_Pin D5_Pin D6_Pin D11_Pin
                           D12_Pin */
  GPIO_InitStruct.Pin = D4_Pin|D5_Pin|D6_Pin|D11_Pin
                          |D12_Pin;
  GPIO_InitStruct.Mode = GPIO_MODE_AF_PP;
  GPIO_InitStruct.Pull = GPIO_NOPULL;
  GPIO_InitStruct.Speed = GPIO_SPEED_FREQ_VERY_HIGH;
  GPIO_InitStruct.Alternate = GPIO_AF12_FMC;
  HAL_GPIO_Init(GPIOE, &GPIO_InitStruct);

  /*Configure GPIO pins : G4_Pin G5_Pin B6_Pin B7_Pin */
  GPIO_InitStruct.Pin = G4_Pin|G5_Pin|B6_Pin|B7_Pin;
  GPIO_InitStruct.Mode = GPIO_MODE_AF_PP;
  GPIO_InitStruct.Pull = GPIO_NOPULL;
  GPIO_InitStruct.Speed = GPIO_SPEED_FREQ_LOW;
  GPIO_InitStruct.Alternate = GPIO_AF14_LTDC;
  HAL_GPIO_Init(GPIOB, &GPIO_InitStruct);

  /*Configure GPIO pins : OTG_HS_ID_Pin OTG_HS_DM_Pin OTG_HS_DP_Pin */
  GPIO_InitStruct.Pin = OTG_HS_ID_Pin|OTG_HS_DM_Pin|OTG_HS_DP_Pin;
  GPIO_InitStruct.Mode = GPIO_MODE_AF_PP;
  GPIO_InitStruct.Pull = GPIO_NOPULL;
  GPIO_InitStruct.Speed = GPIO_SPEED_FREQ_LOW;
  GPIO_InitStruct.Alternate = GPIO_AF12_OTG_HS_FS;
  HAL_GPIO_Init(GPIOB, &GPIO_InitStruct);

  /*Configure GPIO pin : VBUS_HS_Pin */
  GPIO_InitStruct.Pin = VBUS_HS_Pin;
  GPIO_InitStruct.Mode = GPIO_MODE_INPUT;
  GPIO_InitStruct.Pull = GPIO_NOPULL;
  HAL_GPIO_Init(VBUS_HS_GPIO_Port, &GPIO_InitStruct);

  /*Configure GPIO pins : D13_Pin D0_Pin D1_Pin D2_Pin
                           D3_Pin */
  GPIO_InitStruct.Pin = D13_Pin|D0_Pin|D1_Pin|D2_Pin
                          |D3_Pin;
  GPIO_InitStruct.Mode = GPIO_MODE_AF_PP;
  GPIO_InitStruct.Pull = GPIO_NOPULL;
  GPIO_InitStruct.Speed = GPIO_SPEED_FREQ_VERY_HIGH;
  GPIO_InitStruct.Alternate = GPIO_AF12_FMC;
  HAL_GPIO_Init(GPIOD, &GPIO_InitStruct);

  /*Configure GPIO pins : Relay0_Pin Relay1_Pin RDX_Pin WRX_DCX_Pin */
  GPIO_InitStruct.Pin = Relay0_Pin|Relay1_Pin|RDX_Pin|WRX_DCX_Pin;
  GPIO_InitStruct.Mode = GPIO_MODE_OUTPUT_PP;
  GPIO_InitStruct.Pull = GPIO_NOPULL;
  GPIO_InitStruct.Speed = GPIO_SPEED_FREQ_LOW;
  HAL_GPIO_Init(GPIOD, &GPIO_InitStruct);

  /*Configure GPIO pin : TE_Pin */
  GPIO_InitStruct.Pin = TE_Pin;
  GPIO_InitStruct.Mode = GPIO_MODE_INPUT;
  GPIO_InitStruct.Pull = GPIO_NOPULL;
  HAL_GPIO_Init(TE_GPIO_Port, &GPIO_InitStruct);

  /*Configure GPIO pins : R7_Pin DOTCLK_Pin B3_Pin */
  GPIO_InitStruct.Pin = R7_Pin|DOTCLK_Pin|B3_Pin;
  GPIO_InitStruct.Mode = GPIO_MODE_AF_PP;
  GPIO_InitStruct.Pull = GPIO_NOPULL;
  GPIO_InitStruct.Speed = GPIO_SPEED_FREQ_LOW;
  GPIO_InitStruct.Alternate = GPIO_AF14_LTDC;
  HAL_GPIO_Init(GPIOG, &GPIO_InitStruct);

  /*Configure GPIO pins : STLINK_RX_Pin STLINK_TX_Pin */
  GPIO_InitStruct.Pin = STLINK_RX_Pin|STLINK_TX_Pin;
  GPIO_InitStruct.Mode = GPIO_MODE_AF_PP;
  GPIO_InitStruct.Pull = GPIO_NOPULL;
  GPIO_InitStruct.Speed = GPIO_SPEED_FREQ_VERY_HIGH;
  GPIO_InitStruct.Alternate = GPIO_AF7_USART1;
  HAL_GPIO_Init(GPIOA, &GPIO_InitStruct);

  /*Configure GPIO pins : myio_Pin myio2_Pin */
  GPIO_InitStruct.Pin = myio_Pin|myio2_Pin;
  GPIO_InitStruct.Mode = GPIO_MODE_OUTPUT_PP;
  GPIO_InitStruct.Pull = GPIO_NOPULL;
  GPIO_InitStruct.Speed = GPIO_SPEED_FREQ_LOW;
  HAL_GPIO_Init(GPIOA, &GPIO_InitStruct);

  /*Configure GPIO pin : PA15 */
  GPIO_InitStruct.Pin = GPIO_PIN_15;
  GPIO_InitStruct.Mode = GPIO_MODE_IT_RISING;
  GPIO_InitStruct.Pull = GPIO_NOPULL;
  HAL_GPIO_Init(GPIOA, &GPIO_InitStruct);

  /*Configure GPIO pin : R2_Pin */
  GPIO_InitStruct.Pin = R2_Pin;
  GPIO_InitStruct.Mode = GPIO_MODE_AF_PP;
  GPIO_InitStruct.Pull = GPIO_NOPULL;
  GPIO_InitStruct.Speed = GPIO_SPEED_FREQ_LOW;
  GPIO_InitStruct.Alternate = GPIO_AF14_LTDC;
  HAL_GPIO_Init(R2_GPIO_Port, &GPIO_InitStruct);

  /*Configure GPIO pins : G7_Pin B2_Pin */
  GPIO_InitStruct.Pin = G7_Pin|B2_Pin;
  GPIO_InitStruct.Mode = GPIO_MODE_AF_PP;
  GPIO_InitStruct.Pull = GPIO_NOPULL;
  GPIO_InitStruct.Speed = GPIO_SPEED_FREQ_LOW;
  GPIO_InitStruct.Alternate = GPIO_AF14_LTDC;
  HAL_GPIO_Init(GPIOD, &GPIO_InitStruct);

  /*Configure GPIO pins : G3_Pin B4_Pin */
  GPIO_InitStruct.Pin = G3_Pin|B4_Pin;
  GPIO_InitStruct.Mode = GPIO_MODE_AF_PP;
  GPIO_InitStruct.Pull = GPIO_NOPULL;
  GPIO_InitStruct.Speed = GPIO_SPEED_FREQ_LOW;
  GPIO_InitStruct.Alternate = GPIO_AF9_LTDC;
  HAL_GPIO_Init(GPIOG, &GPIO_InitStruct);

  /*Configure GPIO pins : LD3_Pin LD4_Pin */
  GPIO_InitStruct.Pin = LD3_Pin|LD4_Pin;
  GPIO_InitStruct.Mode = GPIO_MODE_OUTPUT_PP;
  GPIO_InitStruct.Pull = GPIO_NOPULL;
  GPIO_InitStruct.Speed = GPIO_SPEED_FREQ_LOW;
  HAL_GPIO_Init(GPIOG, &GPIO_InitStruct);

  /*Configure GPIO pins : SDCKE1_Pin SDNE1_Pin */
  GPIO_InitStruct.Pin = SDCKE1_Pin|SDNE1_Pin;
  GPIO_InitStruct.Mode = GPIO_MODE_AF_PP;
  GPIO_InitStruct.Pull = GPIO_NOPULL;
  GPIO_InitStruct.Speed = GPIO_SPEED_FREQ_VERY_HIGH;
  GPIO_InitStruct.Alternate = GPIO_AF12_FMC;
  HAL_GPIO_Init(GPIOB, &GPIO_InitStruct);

  /*Configure GPIO pin : hall_0_Pin */
  GPIO_InitStruct.Pin = hall_0_Pin;
  GPIO_InitStruct.Mode = GPIO_MODE_IT_RISING;
  GPIO_InitStruct.Pull = GPIO_PULLUP;
  HAL_GPIO_Init(hall_0_GPIO_Port, &GPIO_InitStruct);

  /* EXTI interrupt init*/
  HAL_NVIC_SetPriority(EXTI0_IRQn, 0, 0);
  HAL_NVIC_EnableIRQ(EXTI0_IRQn);

}

/* USER CODE BEGIN 4 */

void HAL_GPIO_EXTI_Callback(uint16_t GPIO_Pin)
{
	if (GPIO_Pin == hall_0_Pin)  // hall sensor
	{
		if (zeroed == 0 && started==1 )
		{
			if (HAL_GPIO_ReadPin(hall_0_GPIO_Port, hall_0_Pin))
			{
				zeroed = 0;
//				HAL_GPIO_TogglePin(LD3_GPIO_Port, LD3_Pin);
				__HAL_TIM_SET_COUNTER(&htim8, 0);

//				if
//
				HAL_GPIO_WritePin(myio2_GPIO_Port, myio2_Pin, 1);
				HAL_GPIO_WritePin(myio2_GPIO_Port, myio2_Pin, 0);

			}
		}
	}
}

void HAL_ADCEx_InjectedConvCpltCallback(ADC_HandleTypeDef* hadc)
{
//	HAL_GPIO_WritePin(myio2_GPIO_Port, myio2_Pin, 1);
//	HAL_GPIO_WritePin(myio2_GPIO_Port, myio2_Pin, 0);
//		HAL_GPIO_TogglePin(myio_GPIO_Port, myio_Pin);
//		adc[0] = HAL_ADCEx_InjectedGetValue(&hadc2, 1);
		adc[0] += HAL_ADCEx_InjectedGetValue(&hadc1, 1);
		adc[1] += HAL_ADCEx_InjectedGetValue(&hadc2, 1);
		adc[2] += HAL_ADCEx_InjectedGetValue(&hadc3, 1);

		if (cycle_count == 100 )
		{
			if(adc[0]+adc[1]+adc[2] > 50000)
			{
				fault = 1;
				HAL_GPIO_WritePin(LD4_GPIO_Port, LD4_Pin, 1);
			}
//			int length = sprintf(tx_buffer, "%d,%d,%f,%d\r\n", vel, error, m, angle);
			int length = sprintf(tx_buffer, "%d,%f,%d,%f,%u,%u,%u\r\n", vel, integral, angle, m, adc[0], adc[1], adc[2]);

			HAL_UART_Transmit_IT(&huart5, tx_buffer, length);
			cycle_count = 0;
			adc[0] = 0;
			adc[1] = 0;
			adc[2] = 0;
//			HAL_GPIO_WritePin(myio_GPIO_Port, myio_Pin, 1);

		}
		cycle_count+=1;
//		HAL_GPIO_WritePin(myio_GPIO_Port, myio_Pin, 0);

//		if (tx_bytes + length+1 >= MAX_TX)
//		{
////			HAL_UART_Transmit_IT(&huart5, tx_buffer, tx_bytes);
//			// send it and
//			tx_bytes = 0;
//			cycle_count = 0;

//
//		}
}

//void HAL_TIM_OC_DelayElapsedCallback(TIM_HandleTypeDef *htim)
//{
//	if (htim->Instance == TIM1)
//	{
//		if (htim->Channel == HAL_TIM_ACTIVE_CHANNEL_4)
//		{	//      HAL_IncTick();
//			HAL_GPIO_WritePin(myio_GPIO_Port, myio_Pin, 1);
//			HAL_GPIO_WritePin(myio_GPIO_Port, myio_Pin, 0);
//		}
//	}
//}

/* USER CODE END 4 */

 /**
  * @brief  Period elapsed callback in non blocking mode
  * @note   This function is called  when TIM6 interrupt took place, inside
  * HAL_TIM_IRQHandler(). It makes a direct call to HAL_IncTick() to increment
  * a global variable "uwTick" used as application time base.
  * @param  htim : TIM handle
  * @retval None
  */
void HAL_TIM_PeriodElapsedCallback(TIM_HandleTypeDef *htim)
{
  /* USER CODE BEGIN Callback 0 */

  if (htim->Instance == TIM6) {

    elapsed_ms++;
    if (elapsed_ms == 4)
    {
    	int old_vel = vel;
    	elapsed_ms = 0;
    	if (underflow)
    	{
    		dir = 1; // adasd
    	}
    	else
    	{
    		dir = 1;
    	}
    	if (dir)  // clockwise rotation
		{
			if (angle >= last_angle)
			{
				vel = angle - last_angle;
			}
			else
			{
				vel = angle + 360 -last_angle;
			}
			if (vel > 200)
			{
				vel = old_vel;
			}
    	}
    	else  // anti-clockwise rotation
		{
			if (last_angle >= angle)
			{
				vel = last_angle - angle;
			}
			else
			{
				vel =  360 - angle + last_angle;
			}
    	}
		last_angle = angle;
    }
//    pid();
    if (fault == 0)
    {
		if (!HAL_GPIO_ReadPin(VFO_GPIO_Port, VFO_Pin))
		{
			HAL_GPIO_WritePin(LD4_GPIO_Port, LD4_Pin, 1);
			fault = 1;

		}
		pid();
    }
  }

  /* USER CODE END Callback 0 */
  if (htim->Instance == TIM6) {
    HAL_IncTick();
  }
  /* USER CODE BEGIN Callback 1 */
  if (htim->Instance == TIM1) {
	  myisr();
//      HAL_IncTick();
//		HAL_GPIO_WritePin(myio_GPIO_Port, myio_Pin, 1);
//		HAL_GPIO_WritePin(myio_GPIO_Port, myio_Pin, 0);

    }

  if (htim->Instance == TIM8)
  {
	  if (__HAL_TIM_GET_COUNTER(&htim8)>1200)
	  {
		  underflow = 1;
	  }
	  else
	  {
		  underflow = 0;
	  }
  }
  /* USER CODE END Callback 1 */
}

void Error_Handler(void)
{
}

/************************ (C) COPYRIGHT STMicroelectronics *****END OF FILE****/
